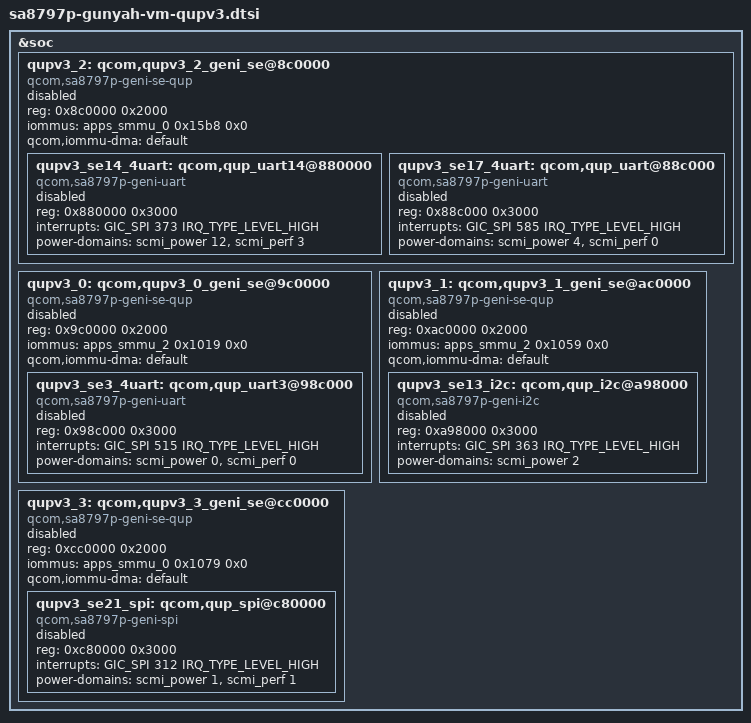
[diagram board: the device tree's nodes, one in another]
// SPDX-License-Identifier: BSD-3-Clause
/*
 * Copyright (c) Qualcomm Technologies, Inc. and/or its subsidiaries.
 */

&soc {
	/* QUPv3_2  wrapper  instance */
	qupv3_2: qcom,qupv3_2_geni_se@8c0000 {
		compatible = "qcom,sa8797p-geni-se-qup", "qcom,sa8255p-geni-se-qup";
		reg = <0x8c0000 0x2000>;
		#address-cells = <1>;
		#size-cells = <1>;
		ranges;
		iommus = <&apps_smmu_0 0x15b8 0x0>;
		qcom,iommu-dma = "default";
		status = "disabled";

		/* BT UART Instances */
		qupv3_se14_4uart: qcom,qup_uart14@880000 {
			compatible = "qcom,sa8797p-geni-uart", "qcom,sa8255p-geni-uart";
			reg = <0x880000 0x3000>;
			interrupts = <GIC_SPI 373 IRQ_TYPE_LEVEL_HIGH>;
			power-domains = <&scmi_power 12>, <&scmi_perf 3>;
			power-domain-names = "power", "perf";
			status = "disabled";
		};

		qupv3_se17_4uart: qcom,qup_uart@88c000 {
			compatible = "qcom,sa8797p-geni-uart", "qcom,sa8255p-geni-uart";
			reg = <0x88c000 0x3000>;
			interrupts = <GIC_SPI 585 IRQ_TYPE_LEVEL_HIGH>;
			power-domains = <&scmi_power 4>, <&scmi_perf 0>;
			power-domain-names = "power", "perf";
			status = "disabled";
		};
	};

	/* QUPv3_0  wrapper  instance */
	qupv3_0: qcom,qupv3_0_geni_se@9c0000 {
		compatible = "qcom,sa8797p-geni-se-qup", "qcom,sa8255p-geni-se-qup";
		reg = <0x9c0000 0x2000>;
		#address-cells = <1>;
		#size-cells = <1>;
		ranges;
		iommus = <&apps_smmu_2 0x1019 0x0>;
		qcom,iommu-dma = "default";
		status = "disabled";

		qupv3_se3_4uart: qcom,qup_uart3@98c000 {
			compatible = "qcom,sa8797p-geni-uart", "qcom,sa8255p-geni-uart";
			reg = <0x98c000 0x3000>;
			interrupts = <GIC_SPI 515 IRQ_TYPE_LEVEL_HIGH>;
			power-domains = <&scmi_power 0>, <&scmi_perf 0>;
			power-domain-names = "power", "perf";
			status = "disabled";
		};
	};

	/* QUPv3_1  wrapper  instance */
	qupv3_1: qcom,qupv3_1_geni_se@ac0000 {
		compatible = "qcom,sa8797p-geni-se-qup", "qcom,sa8255p-geni-se-qup";
		reg = <0xac0000 0x2000>;
		#address-cells = <1>;
		#size-cells = <1>;
		ranges;
		iommus = <&apps_smmu_2 0x1059 0x0>;
		qcom,iommu-dma = "default";
		status = "disabled";

		qupv3_se13_i2c: qcom,qup_i2c@a98000 {
			compatible = "qcom,sa8797p-geni-i2c", "qcom,sa8255p-geni-i2c";
			reg = <0xa98000 0x3000>;
			interrupts = <GIC_SPI 363 IRQ_TYPE_LEVEL_HIGH>;
			power-domains = <&scmi_power 2>;
			status = "disabled";
		};
	};

	/* QUPv3_3  wrapper  instance */
	qupv3_3: qcom,qupv3_3_geni_se@cc0000 {
		compatible = "qcom,sa8797p-geni-se-qup", "qcom,sa8255p-geni-se-qup";
		reg = <0xcc0000 0x2000>;
		#address-cells = <1>;
		#size-cells = <1>;
		ranges;
		iommus = <&apps_smmu_0 0x1079 0x0>;
		qcom,iommu-dma = "default";
		status = "disabled";

		qupv3_se21_spi: qcom,qup_spi@c80000 {
			compatible = "qcom,sa8797p-geni-spi", "qcom,sa8255p-geni-spi";
			reg = <0xc80000 0x3000>;
			interrupts = <GIC_SPI 312 IRQ_TYPE_LEVEL_HIGH>;
			power-domains = <&scmi_power 1>, <&scmi_perf 1>;
			power-domain-names = "power", "perf";
			status = "disabled";
		};
	};
};
